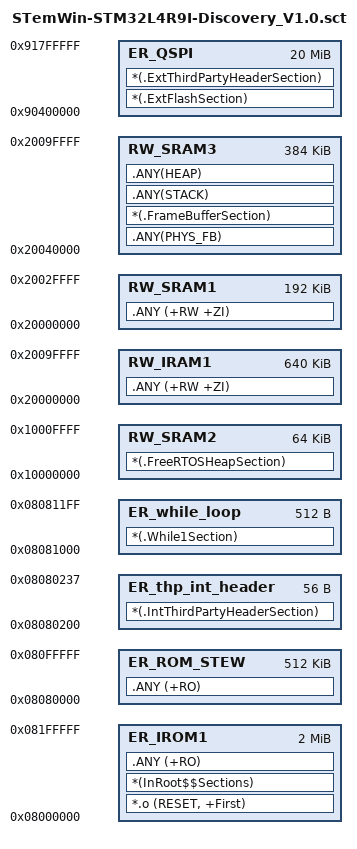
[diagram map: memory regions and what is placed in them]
; *************************************************************
; *** Scatter-Loading Description File generated by uVision ***
; *************************************************************

LR_IROM1 0x08000000 0x00200000  {    ; load region size_region
  ER_IROM1 0x08000000 0x00200000  {  ; load address = execution address
   *.o (RESET, +First)
   *(InRoot$$Sections)
   .ANY (+RO)
  }
  RW_IRAM1 0x20000000  0xA0000 {  ; RW data
   .ANY (+RW +ZI)
  }
  RW_SRAM1 0x20000000  0x30000 {  ; RW data
   .ANY (+RW +ZI)
  }  
  RW_SRAM2 0x10000000  0x10000 {  ; RW data
  *(.FreeRTOSHeapSection)
  }  
  RW_SRAM3 0x20040000  0x60000 {  ; RW data
  .ANY(PHYS_FB)
  *(.FrameBufferSection)
  .ANY(STACK)
  .ANY(HEAP)
  }  
}
LR_ROM_STEW 0x08080000 0x80000 {
 ER_ROM_STEW 0x08080000 0x80000 {
 .ANY (+RO)
      }
}
LR_thp_int_header 0x08080200  0x38 {
 ER_thp_int_header 0x08080200  0x38 {
 *(.IntThirdPartyHeaderSection)
      }
}
LR_while_loop 0x8081000 0x200  {    ; load region size_region
  ER_while_loop 0x8081000  0x200 {  ; load address = execution address
     *(.While1Section)
     }
}

LR_QSPI 0x90400000 0x1400000  {    ; load region size_region
  ER_QSPI 0x90400000 0x1400000  {  ; load address = execution address
   *(.ExtFlashSection)
     *(.ExtThirdPartyHeaderSection)
     }
}

